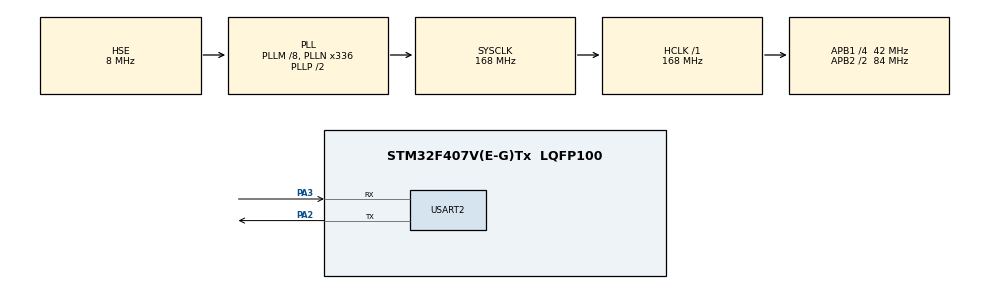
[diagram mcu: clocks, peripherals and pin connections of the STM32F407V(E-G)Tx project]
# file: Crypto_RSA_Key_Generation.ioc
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MBEDTLS.MBEDTLS_GENPRIME=1
MBEDTLS.MBEDTLS_HAVE_SSE2=1
MBEDTLS.MBEDTLS_MPI_MAX_SIZE=256
MBEDTLS.MBEDTLS_PKCS1_V15=1
MBEDTLS.MBEDTLS_PKCS1_V21=1
MBEDTLS.MBEDTLS_PLATFORM_C=0
MBEDTLS.MBEDTLS_RSA_C=1
Mcu.Family=STM32F4
Mcu.Name=STM32F407V(E-G)Tx
Mcu.Package=LQFP100
NVIC.PriorityGroup=NVIC_PRIORITYGROUP_0
PA13.Mode=Serial_Wire
PA13.Signal=SYS_JTMS-SWDIO
PA14.Mode=Serial_Wire
PA14.Signal=SYS_JTCK-SWCLK
PA2.Mode=Asynchronous
PA2.Signal=USART2_TX
PA3.Mode=Asynchronous
PA3.Signal=USART2_RX
PH0-OSC_IN.Mode=HSE-External-Clock-Source
PH0-OSC_IN.Signal=RCC_OSC_IN
PH1-OSC_OUT.Mode=HSE-External-Clock-Source
PH1-OSC_OUT.Signal=RCC_OSC_OUT
ProjectManager.HeapSize=0x200
ProjectManager.StackSize=0x400
ProjectManager.TargetToolchain=STM32CubeIDE
RCC.48MHZClocksFreq_Value=48000000
RCC.AHBFreq_Value=168000000
RCC.APB1CLKDivider=RCC_HCLK_DIV4
RCC.APB1Freq_Value=42000000
RCC.APB1TimFreq_Value=84000000
RCC.APB2CLKDivider=RCC_HCLK_DIV2
RCC.APB2Freq_Value=84000000
RCC.APB2TimFreq_Value=168000000
RCC.CortexFreq_Value=168000000
RCC.HCLKFreq_Value=168000000
RCC.HSE_VALUE=8000000
RCC.HSI_VALUE=16000000
RCC.PLLM=8
RCC.PLLN=336
RCC.PLLQ=7
RCC.PLLSourceVirtual=RCC_PLLSOURCE_HSE
RCC.SYSCLKFreq_VALUE=168000000
RCC.SYSCLKSource=RCC_SYSCLKSOURCE_PLLCLK
RCC.VCOOutputFreq_Value=336000000
USART2.VirtualMode=VM_ASYNC
VP_MBEDTLS_VS_MBEDTLS.Mode=Enabled
VP_RNG_VS_RNG.Mode=RNG_Activate
board=STM32F407G-DISC1

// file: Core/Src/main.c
/* USER CODE BEGIN Header */
/**
  ******************************************************************************
  * @file           : main.c
  * @brief          : Main program body
  ******************************************************************************
  * @attention
  *
  * Copyright (c) 2026 STMicroelectronics.
  * All rights reserved.
  *
  * This software is licensed under terms that can be found in the LICENSE file
  * in the root directory of this software component.
  * If no LICENSE file comes with this software, it is provided AS-IS.
  *
  ******************************************************************************
  */
/* USER CODE END Header */
#include "main.h"
#include "mbedtls.h"

/* USER CODE BEGIN Includes */

#include "mbedtls/rsa.h"
#include "mbedtls/ctr_drbg.h"
#include "mbedtls/entropy.h"
#include <string.h>
#include <stdio.h>

/* USER CODE END Includes */

RNG_HandleTypeDef hrng;

UART_HandleTypeDef huart2;

void SystemClock_Config(void);
static void MX_GPIO_Init(void);
static void MX_RNG_Init(void);
static void MX_USART2_UART_Init(void);

/* USER CODE BEGIN 0 */

void UART_Print(char *msg)
{
    HAL_UART_Transmit(&huart2, (uint8_t *)msg, strlen(msg), HAL_MAX_DELAY);
}

static void print_hex(const char *label, const uint8_t *buf, uint32_t len)
{
    char tmp[8];

    UART_Print((char *)label);
    UART_Print(": ");

    for (uint32_t i = 0; i < len; i++)
    {
        sprintf(tmp, "%02X", buf[i]);
        UART_Print(tmp);
    }

    UART_Print("\r\n");
}

static int rsa_keygen_demo_2048(void)
{
    int ret = 0;
    char msg[80];

    mbedtls_rsa_context rsa;
    mbedtls_entropy_context entropy;
    mbedtls_ctr_drbg_context drbg;

    /* RSA core parameters in raw big-endian form */
    uint8_t N[256] = {0};   /* 2048-bit modulus */
    uint8_t P[128] = {0};   /* 1024-bit prime */
    uint8_t Q[128] = {0};   /* 1024-bit prime */
    uint8_t D[256] = {0};   /* private exponent */
    uint8_t E[8]   = {0};   /* public exponent, e.g. 65537 */

    mbedtls_rsa_init(&rsa, MBEDTLS_RSA_PKCS_V15, 0);
    mbedtls_entropy_init(&entropy);
    mbedtls_ctr_drbg_init(&drbg);

    UART_Print("Seeding DRBG...\r\n");
    ret = mbedtls_ctr_drbg_seed(&drbg,
                                mbedtls_entropy_func,
                                &entropy,
                                (const unsigned char *)"rsa_keygen_demo",
                                strlen("rsa_keygen_demo"));

    sprintf(msg, "ctr_drbg_seed ret = %d\r\n", ret);
    UART_Print(msg);

    if (ret != 0)
    {
        UART_Print("CTR_DRBG seed failed\r\n");
        goto cleanup;
    }

    UART_Print("Generating RSA-2048 key...\r\n");

    /* Generate 2048-bit RSA keypair with public exponent 65537 */
    ret = mbedtls_rsa_gen_key(&rsa,
                              mbedtls_ctr_drbg_random,
                              &drbg,
                              2048,
                              65537);
    if (ret != 0)
    {
        UART_Print("RSA key generation failed\r\n");
        goto cleanup;
    }

    ret = mbedtls_rsa_check_privkey(&rsa);
    if (ret != 0)
    {
        UART_Print("RSA private key check failed\r\n");
        goto cleanup;
    }

    ret = mbedtls_rsa_export_raw(&rsa,
                                 N, sizeof(N),
                                 P, sizeof(P),
                                 Q, sizeof(Q),
                                 D, sizeof(D),
                                 E, sizeof(E));
    if (ret != 0)
    {
        UART_Print("RSA export failed\r\n");
        goto cleanup;
    }

    UART_Print("\r\n=== RSA-2048 KEY GENERATION ===\r\n");
    UART_Print("RSA keypair generated successfully\r\n");

    print_hex("N (modulus)", N, sizeof(N));
    print_hex("E (public exponent)", E, sizeof(E));
    print_hex("D (private exponent)", D, sizeof(D));
    print_hex("P (prime 1)", P, sizeof(P));
    print_hex("Q (prime 2)", Q, sizeof(Q));

cleanup:
    mbedtls_rsa_free(&rsa);
    mbedtls_ctr_drbg_free(&drbg);
    mbedtls_entropy_free(&entropy);

    return ret;
}

/* USER CODE END 0 */

int main(void)
{

  /* MCU Configuration--------------------------------------------------------*/

  /* Reset of all peripherals, Initializes the Flash interface and the Systick. */
  HAL_Init();

  /* Configure the system clock */
  SystemClock_Config();

  /* Initialize all configured peripherals */
  MX_GPIO_Init();
  MX_RNG_Init();
  MX_USART2_UART_Init();
  MX_MBEDTLS_Init();
  /* USER CODE BEGIN 2 */

  if (rsa_keygen_demo_2048() == 0)
  {
      UART_Print("RSA DEMO OK\r\n");
  }
  else
  {
      UART_Print("RSA DEMO FAILED\r\n");
  }

  /* USER CODE END 2 */

  /* Infinite loop */
  while (1)
  {

  }
}

void SystemClock_Config(void)
{
  RCC_OscInitTypeDef RCC_OscInitStruct = {0};
  RCC_ClkInitTypeDef RCC_ClkInitStruct = {0};

  /** Configure the main internal regulator output voltage
  */
  __HAL_RCC_PWR_CLK_ENABLE();
  __HAL_PWR_VOLTAGESCALING_CONFIG(PWR_REGULATOR_VOLTAGE_SCALE1);

  /** Initializes the RCC Oscillators according to the specified parameters
  * in the RCC_OscInitTypeDef structure.
  */
  RCC_OscInitStruct.OscillatorType = RCC_OSCILLATORTYPE_HSE;
  RCC_OscInitStruct.HSEState = RCC_HSE_BYPASS;
  RCC_OscInitStruct.PLL.PLLState = RCC_PLL_ON;
  RCC_OscInitStruct.PLL.PLLSource = RCC_PLLSOURCE_HSE;
  RCC_OscInitStruct.PLL.PLLM = 8;
  RCC_OscInitStruct.PLL.PLLN = 336;
  RCC_OscInitStruct.PLL.PLLP = RCC_PLLP_DIV2;
  RCC_OscInitStruct.PLL.PLLQ = 7;
  if (HAL_RCC_OscConfig(&RCC_OscInitStruct) != HAL_OK)
  {
    Error_Handler();
  }

  /** Initializes the CPU, AHB and APB buses clocks
  */
  RCC_ClkInitStruct.ClockType = RCC_CLOCKTYPE_HCLK|RCC_CLOCKTYPE_SYSCLK
                              |RCC_CLOCKTYPE_PCLK1|RCC_CLOCKTYPE_PCLK2;
  RCC_ClkInitStruct.SYSCLKSource = RCC_SYSCLKSOURCE_PLLCLK;
  RCC_ClkInitStruct.AHBCLKDivider = RCC_SYSCLK_DIV1;
  RCC_ClkInitStruct.APB1CLKDivider = RCC_HCLK_DIV4;
  RCC_ClkInitStruct.APB2CLKDivider = RCC_HCLK_DIV2;

  if (HAL_RCC_ClockConfig(&RCC_ClkInitStruct, FLASH_LATENCY_5) != HAL_OK)
  {
    Error_Handler();
  }
}

static void MX_RNG_Init(void)
{

  hrng.Instance = RNG;
  if (HAL_RNG_Init(&hrng) != HAL_OK)
  {
    Error_Handler();
  }

}

static void MX_USART2_UART_Init(void)
{

  huart2.Instance = USART2;
  huart2.Init.BaudRate = 115200;
  huart2.Init.WordLength = UART_WORDLENGTH_8B;
  huart2.Init.StopBits = UART_STOPBITS_1;
  huart2.Init.Parity = UART_PARITY_NONE;
  huart2.Init.Mode = UART_MODE_TX_RX;
  huart2.Init.HwFlowCtl = UART_HWCONTROL_NONE;
  huart2.Init.OverSampling = UART_OVERSAMPLING_16;
  if (HAL_UART_Init(&huart2) != HAL_OK)
  {
    Error_Handler();
  }

}

static void MX_GPIO_Init(void)
{

  /* GPIO Ports Clock Enable */
  __HAL_RCC_GPIOH_CLK_ENABLE();
  __HAL_RCC_GPIOA_CLK_ENABLE();

}

void Error_Handler(void)
{
  __disable_irq();
  while (1)
  {
  }
}
